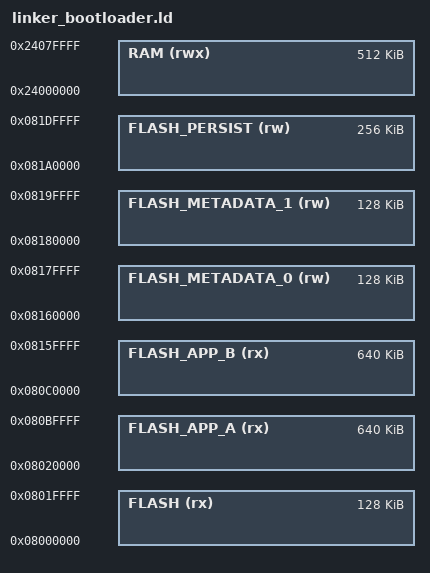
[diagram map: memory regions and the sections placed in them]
/* STM32H7 internal-flash template. Adjust for the exact dual-bank layout. */
MEMORY
{
  FLASH (rx) : ORIGIN = 0x08000000, LENGTH = 128K
  FLASH_APP_A (rx) : ORIGIN = 0x08020000, LENGTH = 640K
  FLASH_APP_B (rx) : ORIGIN = 0x080C0000, LENGTH = 640K
  FLASH_METADATA_0 (rw) : ORIGIN = 0x08160000, LENGTH = 128K
  FLASH_METADATA_1 (rw) : ORIGIN = 0x08180000, LENGTH = 128K
  FLASH_PERSIST (rw) : ORIGIN = 0x081A0000, LENGTH = 256K
  RAM (rwx)  : ORIGIN = 0x24000000, LENGTH = 512K
}
